AUTOSAR XML (schema 4-0-3)
standard types defined: Boolean, UInt16, UInt32
package /AUTOSAR_Platform/DataConstrs
  range DC_Boolean: raw 0..1
  range DC_UInt16: raw 0..65535
package /PATAC/MSM/ComponentTypes
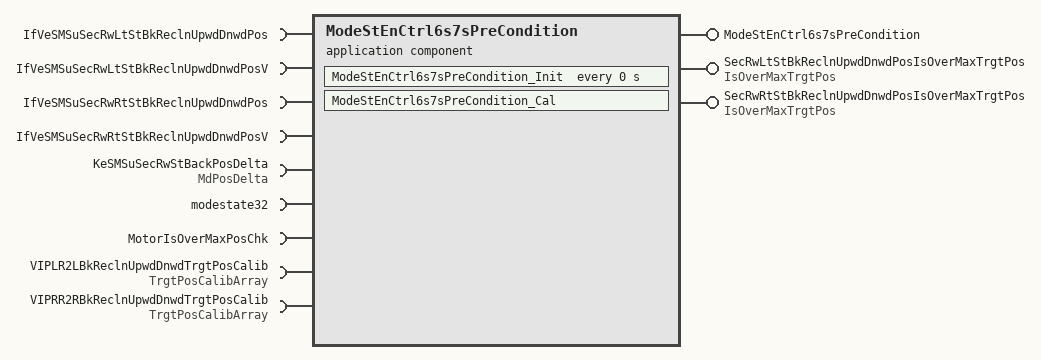
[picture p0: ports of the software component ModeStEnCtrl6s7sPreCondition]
  application sw component type ModeStEnCtrl6s7sPreCondition
    provide port ModeStEnCtrl6s7sPreCondition: server-com-spec{operation=ModeStEnCtrl6s7sPreCondition/Cal, queue-length=1}, provided-interface=ModeStEnCtrl6s7sPreCondition
    provide port SecRwLtStBkReclnUpwdDnwdPosIsOverMaxTrgtPos: nonqueued-sender-com-spec=data-element=IsOverMaxTrgtPos/Val, provided-interface=IsOverMaxTrgtPos
    provide port SecRwRtStBkReclnUpwdDnwdPosIsOverMaxTrgtPos: nonqueued-sender-com-spec=data-element=IsOverMaxTrgtPos/Val, provided-interface=IsOverMaxTrgtPos
    9 x require port:
      IfVeSMSuSecRwLtStBkReclnUpwdDnwdPos: nonqueued-receiver-com-spec{data-element=IfVeSMSuSecRwLtStBkReclnUpwdDnwdPos/Val, filter=data-filter-type=ALWAYS, init-value=0}, required-interface=IfVeSMSuSecRwLtStBkReclnUpwdDnwdPos
      IfVeSMSuSecRwLtStBkReclnUpwdDnwdPosV: nonqueued-receiver-com-spec{data-element=IfVeSMSuSecRwLtStBkReclnUpwdDnwdPosV/Val, filter=data-filter-type=ALWAYS, init-value=0}, required-interface=IfVeSMSuSecRwLtStBkReclnUpwdDnwdPosV
      IfVeSMSuSecRwRtStBkReclnUpwdDnwdPos: nonqueued-receiver-com-spec{data-element=IfVeSMSuSecRwRtStBkReclnUpwdDnwdPos/Val, filter=data-filter-type=ALWAYS, init-value=0}, required-interface=IfVeSMSuSecRwRtStBkReclnUpwdDnwdPos
      IfVeSMSuSecRwRtStBkReclnUpwdDnwdPosV: nonqueued-receiver-com-spec{data-element=IfVeSMSuSecRwRtStBkReclnUpwdDnwdPosV/Val, filter=data-filter-type=ALWAYS, init-value=0}, required-interface=IfVeSMSuSecRwRtStBkReclnUpwdDnwdPosV
      KeSMSuSecRwStBackPosDelta: parameter-require-com-spec{init-value=150, parameter=Val}, required-interface=MdPosDelta
      modestate32: nonqueued-receiver-com-spec{data-element=modestate32/Val, filter=data-filter-type=ALWAYS, init-value=0}, required-interface=modestate32
      MotorIsOverMaxPosChk: client-com-spec=MotorIsOverMaxPosChk/Cal, required-interface=MotorIsOverMaxPosChk
      VIPLR2LBkReclnUpwdDnwdTrgtPosCalib: nonqueued-receiver-com-spec{data-element=TrgtPosArray, filter=data-filter-type=ALWAYS, init-value=[4095, 4095, 4095]}, required-interface=TrgtPosCalibArray
      VIPRR2RBkReclnUpwdDnwdTrgtPosCalib: nonqueued-receiver-com-spec{data-element=TrgtPosArray, filter=data-filter-type=ALWAYS, init-value=[4095, 4095, 4095]}, required-interface=TrgtPosCalibArray
    behavior ModeStEnCtrl6s7sPreCondition_InternalBehavior
      operation invoked event OIT_ModeStEnCtrl6s7sPreCondition_Cal_ModeStEnCtrl6s7sPreCondition_Cal: start-on-event=ModeStEnCtrl6s7sPreCondition_Cal, operation=ModeStEnCtrl6s7sPreCondition.Cal
      timing event ModeStEnCtrl6s7sPreCondition_InitEvent: start-on-event=ModeStEnCtrl6s7sPreCondition_Init, period=0
      runnable ModeStEnCtrl6s7sPreCondition_Cal
        data-receive-point-by-arguments:
          7 x access:
            REC_IfVeSMSuSecRwLtStBkReclnUpwdDnwdPos_Val: accessed-variable=IfVeSMSuSecRwLtStBkReclnUpwdDnwdPos.Val
            REC_IfVeSMSuSecRwLtStBkReclnUpwdDnwdPosV_Val: accessed-variable=IfVeSMSuSecRwLtStBkReclnUpwdDnwdPosV.Val
            REC_IfVeSMSuSecRwRtStBkReclnUpwdDnwdPos_Val: accessed-variable=IfVeSMSuSecRwRtStBkReclnUpwdDnwdPos.Val
            REC_IfVeSMSuSecRwRtStBkReclnUpwdDnwdPosV_Val: accessed-variable=IfVeSMSuSecRwRtStBkReclnUpwdDnwdPosV.Val
            REC_modestate32_Val: accessed-variable=modestate32.Val
            REC_VIPLR2LBkReclnUpwdDnwdTrgtPosCalib_TrgtPosArray: accessed-variable=VIPLR2LBkReclnUpwdDnwdTrgtPosCalib.TrgtPosArray
            REC_VIPRR2RBkReclnUpwdDnwdTrgtPosCalib_TrgtPosArray: accessed-variable=VIPRR2RBkReclnUpwdDnwdTrgtPosCalib.TrgtPosArray
        data-send-points:
          access SEND_SecRwLtStBkReclnUpwdDnwdPosIsOverMaxTrgtPos_Val: accessed-variable=SecRwLtStBkReclnUpwdDnwdPosIsOverMaxTrgtPos.Val
          access SEND_SecRwRtStBkReclnUpwdDnwdPosIsOverMaxTrgtPos_Val: accessed-variable=SecRwRtStBkReclnUpwdDnwdPosIsOverMaxTrgtPos.Val
        parameter access PA_KeSMSuSecRwStBackPosDelta_Val: accessed-parameter=KeSMSuSecRwStBackPosDelta.Val
        sync call SC_MotorIsOverMaxPosChk_Cal: operation=MotorIsOverMaxPosChk.Cal, timeout=0
      runnable ModeStEnCtrl6s7sPreCondition_Init
        parameter access PA_KeSMSuSecRwStBackPosDelta_Val: accessed-parameter=KeSMSuSecRwStBackPosDelta.Val
  swc implementation ModeStEnCtrl6s7sPreCondition_Implementation: behavior=ModeStEnCtrl6s7sPreCondition_InternalBehavior
    code-descriptors:
      code Default: artifact-descriptors=autosar-engineering-object={short-label=Default, category=SWSRC}
package /PATAC/MSM/ModeAdjust/CalPortInterface
  parameter interface MdPosDelta
    parameter data prototype Val: sw-calibration-access=READ-WRITE, type=UInt16
package /PATAC/MSM/ModeAdjust/DataType
  impl type TrgtPosCalibArray: category=ARRAY, sw-calibration-access=READ-ONLY, type-emitter=RTE  # 0:pos 1:max 2:min
    element Element: array-size=3, array-size-semantics=FIXED-SIZE, implementation-data-type=UInt16, invalid-value=0
package /PATAC/MSM/ModeAdjust/Interfaces
  sender receiver interface IfVeSMSuSecRwLtStBkReclnUpwdDnwdPosV: invalidation-policy{data-element=IfVeSMSuSecRwLtStBkReclnUpwdDnwdPosV/Val, handle-invalid=DONT-INVALIDATE}
    data Val: type=Boolean
  sender receiver interface IfVeSMSuSecRwRtStBkReclnUpwdDnwdPosV: invalidation-policy{data-element=IfVeSMSuSecRwRtStBkReclnUpwdDnwdPosV/Val, handle-invalid=DONT-INVALIDATE}
    data Val: type=Boolean
package /PATAC/MSM/ModeAdjust/PortInterface
  client server interface ModeStEnCtrl6s7sPreCondition
    operation Cal
  client server interface MotorIsOverMaxPosChk
    operation Cal
      5 x arg, all with server-argument-impl-policy=USE-ARGUMENT-TYPE:
        PosV: type=Boolean, direction=IN
        Pos: type=UInt16, direction=IN
        TrgtPosCalib: type=TrgtPosCalibArray, direction=IN
        Delta: type=UInt16, direction=IN
        IsOverMaxTrgtPos: type=Boolean, direction=OUT
  sender receiver interface modestate32: invalidation-policy{data-element=modestate32/Val, handle-invalid=DONT-INVALIDATE}
    data Val: type=UInt32
  sender receiver interface TrgtPosCalibArray: invalidation-policy{data-element=TrgtPosArray, handle-invalid=DONT-INVALIDATE}
    data TrgtPosArray: type=TrgtPosCalibArray  # 0:Pos 1:Max 2:Min
package /PATAC/MSM/PortInterfaces
  sender receiver interface IfVeSMSuSecRwLtStBkReclnUpwdDnwdPos: invalidation-policy{data-element=IfVeSMSuSecRwLtStBkReclnUpwdDnwdPos/Val, handle-invalid=DONT-INVALIDATE}
    data Val: type=UInt16
  sender receiver interface IfVeSMSuSecRwRtStBkReclnUpwdDnwdPos: invalidation-policy{data-element=IfVeSMSuSecRwRtStBkReclnUpwdDnwdPos/Val, handle-invalid=DONT-INVALIDATE}
    data Val: type=UInt16
package /PortInterfaces
  sender receiver interface IsOverMaxTrgtPos: invalidation-policy{data-element=IsOverMaxTrgtPos/Val, handle-invalid=DONT-INVALIDATE}
    data Val: type=Boolean
